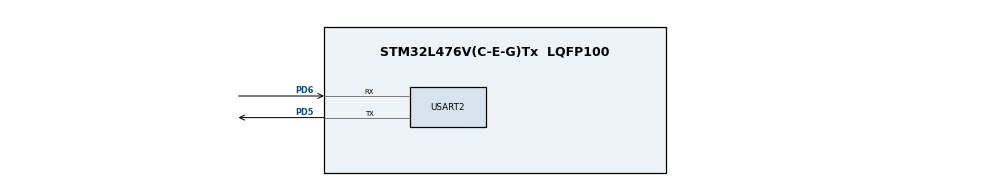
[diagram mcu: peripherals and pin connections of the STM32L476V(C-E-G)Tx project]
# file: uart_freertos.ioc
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FREERTOS.Tasks01=defaultTask,0,128,StartDefaultTask,Default,NULL
Mcu.Family=STM32L4
Mcu.Name=STM32L476V(C-E-G)Tx
Mcu.Package=LQFP100
NVIC.PriorityGroup=NVIC_PRIORITYGROUP_4
NVIC.TIM6_DAC_IRQn=true\:0\:0\:false\:false\:true\:false\:false\:true
NVIC.TimeBase=TIM6_DAC_IRQn
NVIC.TimeBaseIP=TIM6
NVIC.USART2_IRQn=true\:5\:0\:false\:false\:true\:true\:true\:true
PD5.Mode=Asynchronous
PD5.Signal=USART2_TX
PD6.Mode=Asynchronous
PD6.Signal=USART2_RX
ProjectManager.HeapSize=0x200
ProjectManager.StackSize=0x400
ProjectManager.TargetToolchain=EWARM V8
RCC.HSE_VALUE=8000000
RCC.HSI_VALUE=16000000
RCC.LSE_VALUE=32768
RCC.MSI_VALUE=4000000
RCC.VCOOutputFreq_Value=32000000
USART2.VirtualMode-Asynchronous=VM_ASYNC
VP_FREERTOS_VS_CMSIS_V1.Mode=CMSIS_V1
VP_SYS_VS_tim6.Mode=TIM6
board=custom

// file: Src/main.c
/* USER CODE BEGIN Header */
/**
  ******************************************************************************
  * @file           : main.c
  * @brief          : Main program body
  ******************************************************************************
  * @attention
  *
  * <h2><center>&copy; Copyright (c) 2019 STMicroelectronics.
  * All rights reserved.</center></h2>
  *
  * This software component is licensed by ST under BSD 3-Clause license,
  * the "License"; You may not use this file except in compliance with the
  * License. You may obtain a copy of the License at:
  *                        opensource.org/licenses/BSD-3-Clause
  *
  ******************************************************************************
  */
/* USER CODE END Header */

#include "main.h"
#include "cmsis_os.h"

UART_HandleTypeDef huart2;

/* USER CODE BEGIN PV */
osThreadId Thread1Handle, Thread2Handle;
osSemaphoreId osSemaphore;

uint8_t rx_buff[8];
/* USER CODE END PV */

void SystemClock_Config(void);
static void MX_GPIO_Init(void);
static void MX_USART2_UART_Init(void);

/* USER CODE BEGIN PFP */
static void Thread1(void const *argument);
static void Thread2(void const *argument);
/* USER CODE END PFP */

int main(void)
{

  /* MCU Configuration--------------------------------------------------------*/

  /* Reset of all peripherals, Initializes the Flash interface and the Systick. */
  HAL_Init();

  /* Configure the system clock */
  SystemClock_Config();

  /* Initialize all configured peripherals */
  MX_GPIO_Init();
  MX_USART2_UART_Init();
  /* USER CODE BEGIN 2 */
  HAL_UART_Receive_IT(&huart2, rx_buff, 8);
  /* USER CODE END 2 */

  /* USER CODE BEGIN RTOS_SEMAPHORES */
  osSemaphoreDef(SEM);
  osSemaphore = osSemaphoreCreate(osSemaphore(SEM) , 1);
  /* USER CODE END RTOS_SEMAPHORES */

  /* Create the thread(s) */
  /* definition and creation of defaultTask */

  /* USER CODE BEGIN RTOS_THREADS */
  osThreadDef(thread1, Thread1, osPriorityNormal, 0, configMINIMAL_STACK_SIZE);
  Thread1Handle = osThreadCreate(osThread(thread1), (void *) osSemaphore);

  osThreadDef(thread2, Thread2, osPriorityLow, 0, configMINIMAL_STACK_SIZE);
  Thread2Handle = osThreadCreate(osThread(thread2), (void *) osSemaphore);
  /* USER CODE END RTOS_THREADS */

  /* Start scheduler */
  osKernelStart();

  /* We should never get here as control is now taken by the scheduler */

  /* Infinite loop */
  while (1)
  {

  }
}

void SystemClock_Config(void)
{
  RCC_OscInitTypeDef RCC_OscInitStruct = {0};
  RCC_ClkInitTypeDef RCC_ClkInitStruct = {0};
  RCC_PeriphCLKInitTypeDef PeriphClkInit = {0};

  /** Initializes the CPU, AHB and APB busses clocks
  */
  RCC_OscInitStruct.OscillatorType = RCC_OSCILLATORTYPE_MSI;
  RCC_OscInitStruct.MSIState = RCC_MSI_ON;
  RCC_OscInitStruct.MSICalibrationValue = 0;
  RCC_OscInitStruct.MSIClockRange = RCC_MSIRANGE_6;
  RCC_OscInitStruct.PLL.PLLState = RCC_PLL_NONE;
  if (HAL_RCC_OscConfig(&RCC_OscInitStruct) != HAL_OK)
  {
    Error_Handler();
  }
  /** Initializes the CPU, AHB and APB busses clocks
  */
  RCC_ClkInitStruct.ClockType = RCC_CLOCKTYPE_HCLK|RCC_CLOCKTYPE_SYSCLK
                              |RCC_CLOCKTYPE_PCLK1|RCC_CLOCKTYPE_PCLK2;
  RCC_ClkInitStruct.SYSCLKSource = RCC_SYSCLKSOURCE_MSI;
  RCC_ClkInitStruct.AHBCLKDivider = RCC_SYSCLK_DIV1;
  RCC_ClkInitStruct.APB1CLKDivider = RCC_HCLK_DIV1;
  RCC_ClkInitStruct.APB2CLKDivider = RCC_HCLK_DIV1;

  if (HAL_RCC_ClockConfig(&RCC_ClkInitStruct, FLASH_LATENCY_0) != HAL_OK)
  {
    Error_Handler();
  }
  PeriphClkInit.PeriphClockSelection = RCC_PERIPHCLK_USART2;
  PeriphClkInit.Usart2ClockSelection = RCC_USART2CLKSOURCE_PCLK1;
  if (HAL_RCCEx_PeriphCLKConfig(&PeriphClkInit) != HAL_OK)
  {
    Error_Handler();
  }
  /** Configure the main internal regulator output voltage
  */
  if (HAL_PWREx_ControlVoltageScaling(PWR_REGULATOR_VOLTAGE_SCALE1) != HAL_OK)
  {
    Error_Handler();
  }
}

static void MX_USART2_UART_Init(void)
{

  huart2.Instance = USART2;
  huart2.Init.BaudRate = 115200;
  huart2.Init.WordLength = UART_WORDLENGTH_8B;
  huart2.Init.StopBits = UART_STOPBITS_1;
  huart2.Init.Parity = UART_PARITY_NONE;
  huart2.Init.Mode = UART_MODE_TX_RX;
  huart2.Init.HwFlowCtl = UART_HWCONTROL_NONE;
  huart2.Init.OverSampling = UART_OVERSAMPLING_16;
  huart2.Init.OneBitSampling = UART_ONE_BIT_SAMPLE_DISABLE;
  huart2.AdvancedInit.AdvFeatureInit = UART_ADVFEATURE_NO_INIT;
  if (HAL_UART_Init(&huart2) != HAL_OK)
  {
    Error_Handler();
  }

}

static void MX_GPIO_Init(void)
{

  /* GPIO Ports Clock Enable */
  __HAL_RCC_GPIOD_CLK_ENABLE();

}

/* USER CODE BEGIN 4 */
static void Thread1(void const *argument)
{
  osSemaphoreId semaphore = (osSemaphoreId) argument;

  while (1)
  {
    if (semaphore != NULL)
    {
      /* Try to obtain the semaphore */
      if (osSemaphoreWait(semaphore , 100) == osOK)
      {
        HAL_UART_Transmit(&huart2, "Hello from Thread 1\n", 20, 10);
        osSemaphoreRelease(semaphore);
        osDelay(1000);
      }
    }
  }
}

static void Thread2(void const *argument)
{
  osSemaphoreId semaphore = (osSemaphoreId) argument;

  while (1)
  {
    if (semaphore != NULL)
    {
      /* Try to obtain the semaphore */
      if (osSemaphoreWait(semaphore , 100) == osOK)
      {
        HAL_UART_Transmit(&huart2, "Hello from Thread 2\n", 20, 10);
        osSemaphoreRelease(semaphore);
        osDelay(1000);
      }
    }
  }
}

/* USER CODE END 4 */

void HAL_TIM_PeriodElapsedCallback(TIM_HandleTypeDef *htim)
{
  if (htim->Instance == TIM6)
  {
    HAL_IncTick();
  }
}

void Error_Handler(void)
{
}

/************************ (C) COPYRIGHT STMicroelectronics *****END OF FILE****/
